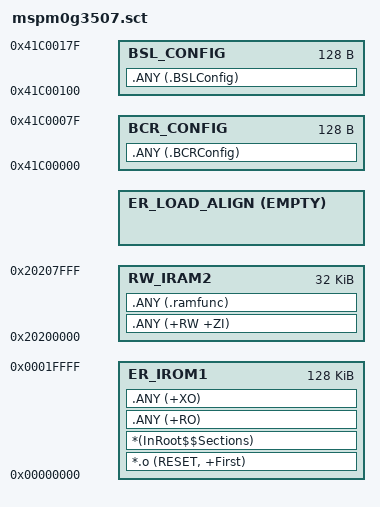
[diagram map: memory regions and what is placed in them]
; *************************************************************
; *** Scatter-Loading Description File generated by uVision ***
; *************************************************************

LR_IROM1 0x00000000 0x00020000  {    ; load region size_region
  ER_IROM1 0x00000000 ALIGNALL 8 0x00020000  {  ; load address = execution address
   *.o (RESET, +First)
   *(InRoot$$Sections)
   .ANY (+RO)
   .ANY (+XO)
  }
  RW_IRAM2 0x20200000 0x00008000  {  ; RW data
   .ANY (+RW +ZI)
   .ANY (.ramfunc)
  }
  ; The TI flash loader rejects a final write whose size is not a multiple
  ; of 8. ALIGNALL above does not align the end of linker-generated tables.
  ; An empty trailing region aligns the load-image end, including any RW
  ; initialization data, without adding executable code or a RAM payload.
  ER_LOAD_ALIGN +0 ALIGN 8 EMPTY 0 {
  }
  ScatterAssert(ImageLimit(ER_LOAD_ALIGN) <= 0x20208000)
}

LR_BCR 0x41C00000 0x00000100  {    ; load region size_region
  BCR_CONFIG 0x41C00000 0x00000080{
	.ANY (.BCRConfig)
  }
}

LR_BSL 0x41C00100 0x00000100  {    ; load region size_region
   BSL_CONFIG 0x41C00100 0x00000080{
	.ANY (.BSLConfig)
  }
}
